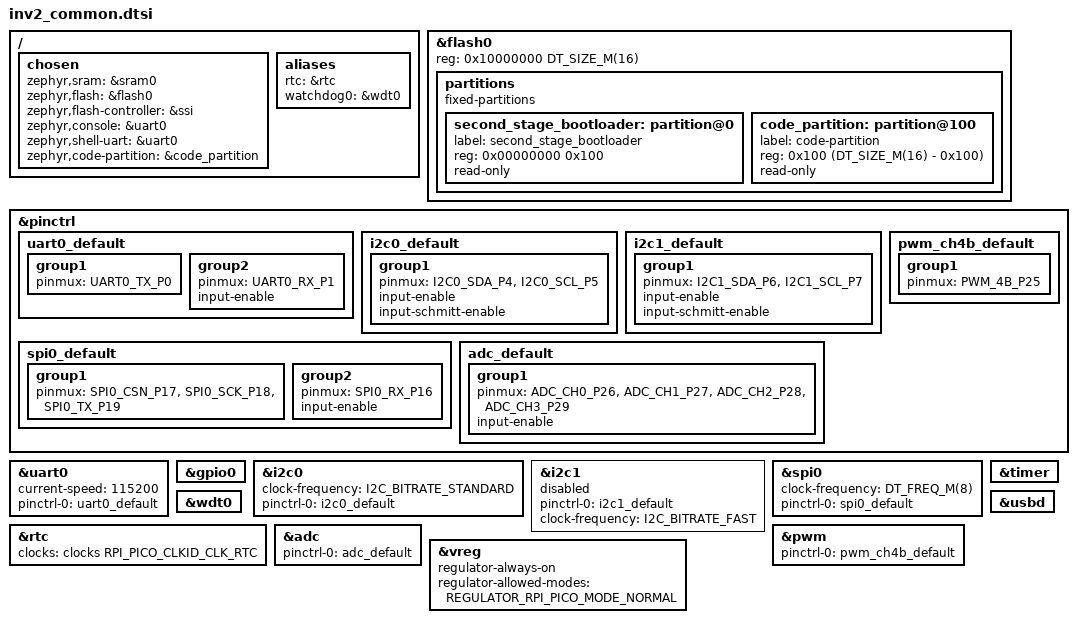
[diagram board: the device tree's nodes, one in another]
/ {
	chosen {
		zephyr,sram = &sram0;
		zephyr,flash = &flash0;
		zephyr,flash-controller = &ssi;
		zephyr,console = &uart0;
		zephyr,shell-uart = &uart0;
		zephyr,code-partition = &code_partition;
	};

	aliases {
		rtc = &rtc;
		watchdog0 = &wdt0;
	};
};

&flash0 {
	reg = <0x10000000 DT_SIZE_M(16)>;

	partitions {
		compatible = "fixed-partitions";
		#address-cells = <1>;
		#size-cells = <1>;

		/* Reserved memory for the second stage bootloader */
		second_stage_bootloader: partition@0 {
			label = "second_stage_bootloader";
			reg = <0x00000000 0x100>;
			read-only;
		};

		/*
		 * Usable flash. Starts at 0x100, after the bootloader. The partition
		 * size is 16MB minus the 0x100 bytes taken by the bootloader.
		 */
		code_partition: partition@100 {
			label = "code-partition";
			reg = <0x100 (DT_SIZE_M(16) - 0x100)>;
			read-only;
		};
	};
};

&pinctrl {
	uart0_default: uart0_default {
		group1 {
			pinmux = <UART0_TX_P0>;
		};
		group2 {
			pinmux = <UART0_RX_P1>;
			input-enable;
		};
	};

	i2c0_default: i2c0_default {
		group1 {
			pinmux = <I2C0_SDA_P4>, <I2C0_SCL_P5>;
			input-enable;
			input-schmitt-enable;
		};
	};

	i2c1_default: i2c1_default {
		group1 {
			pinmux = <I2C1_SDA_P6>, <I2C1_SCL_P7>;
			input-enable;
			input-schmitt-enable;
		};
	};

	spi0_default: spi0_default {
		group1 {
			pinmux = <SPI0_CSN_P17>, <SPI0_SCK_P18>, <SPI0_TX_P19>;
		};
		group2 {
			pinmux = <SPI0_RX_P16>;
			input-enable;
		};
	};

	pwm_ch4b_default: pwm_ch4b_default {
		group1 {
			pinmux = <PWM_4B_P25>;
		};
	};

	adc_default: adc_default {
		group1 {
			pinmux = <ADC_CH0_P26>, <ADC_CH1_P27>, <ADC_CH2_P28>, <ADC_CH3_P29>;
			input-enable;
		};
	};
};

&uart0 {
	current-speed = <115200>;
	status = "okay";
	pinctrl-0 = <&uart0_default>;
	pinctrl-names = "default";
};

&gpio0 {
	status = "okay";
};

&i2c0 {
	clock-frequency = <I2C_BITRATE_STANDARD>;
	status = "okay";
	pinctrl-0 = <&i2c0_default>;
	pinctrl-names = "default";
};

&i2c1 {
	pinctrl-0 = <&i2c1_default>;
	pinctrl-names = "default";
	status = "disabled";
	clock-frequency = <I2C_BITRATE_FAST>;
};

&spi0 {
	clock-frequency = <DT_FREQ_M(8)>;
	status = "okay";
	pinctrl-0 = <&spi0_default>;
	pinctrl-names = "default";
};

&timer {
	status = "okay";
};

&wdt0 {
	status = "okay";
};

&rtc {
	clocks = <&clocks RPI_PICO_CLKID_CLK_RTC>;
	status = "okay";
};

&adc {
	status = "okay";
	pinctrl-0 = <&adc_default>;
	pinctrl-names = "default";
};

&pwm {
	pinctrl-0 = <&pwm_ch4b_default>;
	pinctrl-names = "default";
};

&vreg {
	regulator-always-on;
	regulator-allowed-modes = <REGULATOR_RPI_PICO_MODE_NORMAL>;
};

zephyr_udc0: &usbd {
	status = "okay";
};
